# AT32UC3A1256 device description
Architecture: AVR32_UC3; Family: AVR UC3
Registers are 32-bit, read-write, reset 0x0 unless marked. A register's access mark holds for its fields unless they carry their own. Offsets are from the block's base; [hi:lo] are bit positions; {n}, {i} and the like mark numbered series; 'fields as' and 'values as' point back to an identical list.

## ABDAC — Audio Bitstream DAC
Instances: ABDAC 0xffff4000
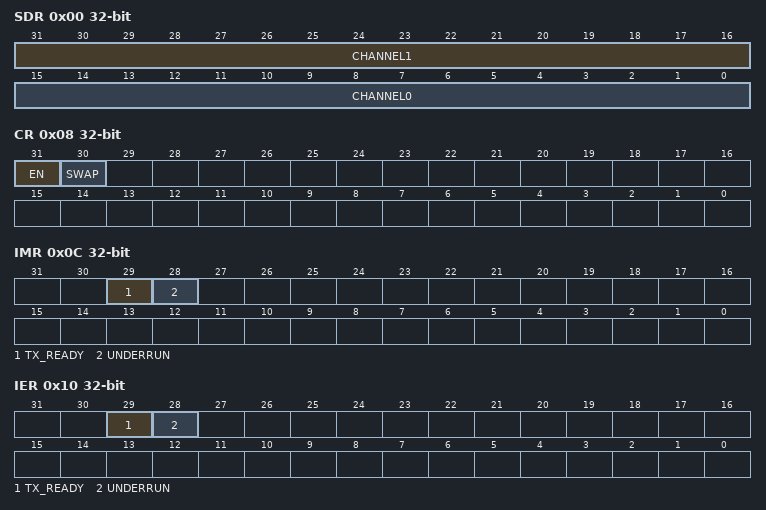
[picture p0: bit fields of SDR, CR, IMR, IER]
0x00 SDR — Sample Data Register
  [31:16] CHANNEL1 — Sample Data for Channel 1
  [15:0] CHANNEL0 — Sample Data for Channel 0
0x08 CR reset not defined — Control Register
  [31] EN — Enable Audio DAC.
  [30] SWAP — Swap Channels
0x0C IMR ro reset not defined — Interrupt Mask Register
  [29] TX_READY — TX Ready Interrupt Mask
  [28] UNDERRUN — Underrun Interrupt Mask
0x10 IER wo reset not defined — Interrupt Enable Register
  [29] TX_READY — TX Ready Interrupt Enable
  [28] UNDERRUN — Underrun Interrupt Enable
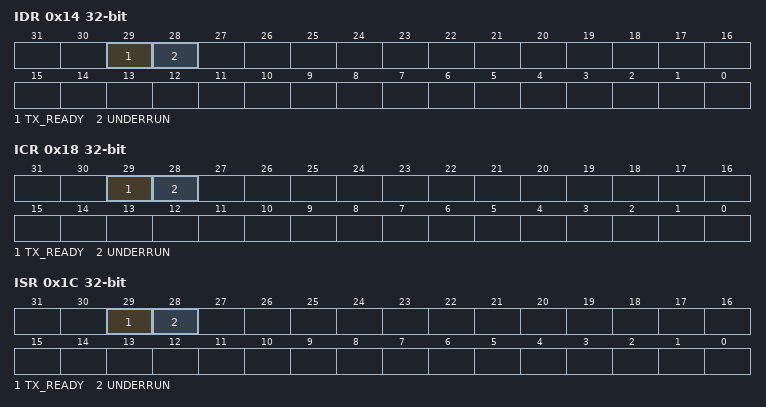
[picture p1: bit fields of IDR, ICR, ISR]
0x14 IDR wo reset not defined — Interupt Disable Register
  [29] TX_READY — TX Ready Interrupt Disable
  [28] UNDERRUN — Underrun Interrupt Disable
0x18 ICR wo reset not defined — Interrupt Clear Register
  [29] TX_READY — TX Ready Interrupt Clear
  [28] UNDERRUN — Underrun Interrupt Clear
0x1C ISR ro reset not defined — Interrupt Status Register
  [29] TX_READY — Interrupt Status Register
  [28] UNDERRUN — Interrupt Status Register

## EIC — External Interrupt Controller
Instances: EIC 0xffff0d80
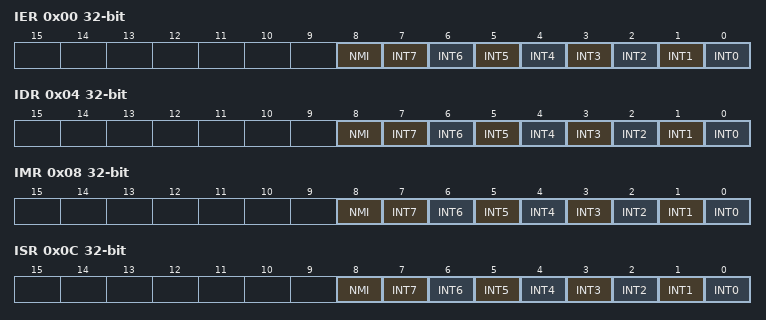
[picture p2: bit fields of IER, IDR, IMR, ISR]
0x00 IER wo — Interrupt Enable Register
  [8] NMI — External Non Maskable CPU interrupt
  [n] INT{n} (n=0..7) — External Interrupt {n}
0x04 IDR wo — Interrupt Disable Register
  fields as IER
0x08 IMR ro — Interrupt Mask Register
  fields as IER
0x0C ISR ro — Interrupt Status Register
  fields as IER
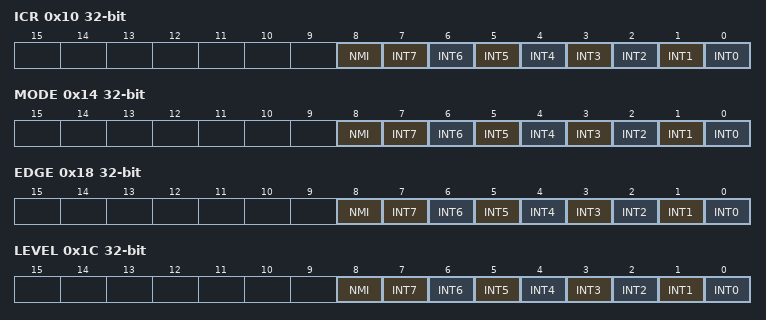
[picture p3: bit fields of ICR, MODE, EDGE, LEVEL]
0x10 ICR wo — Interrupt Clear Register
  fields as IER
0x14 MODE
  fields as IER
0x18 EDGE
  fields as IER
0x1C LEVEL
  fields as IER
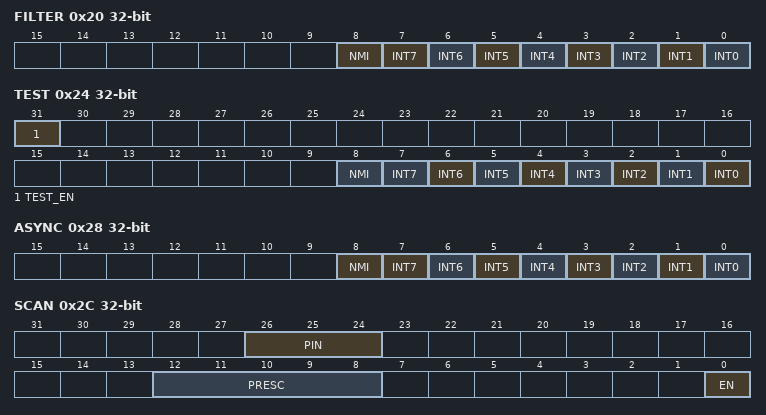
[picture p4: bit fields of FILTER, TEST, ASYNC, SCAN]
0x20 FILTER
  fields as IER
0x24 TEST
  [31] TEST_EN — Test Enable
  [8] NMI — External Non Maskable CPU interrupt
  [n] INT{n} (n=0..7) — External Interrupt {n}
0x28 ASYNC — Asynchronous Mode Register
  fields as IER
0x2C SCAN
  [26:24] PIN — SCAN Pin
  [12:8] PRESC — SCAN Prescale
  [0] EN — SCAN Enable
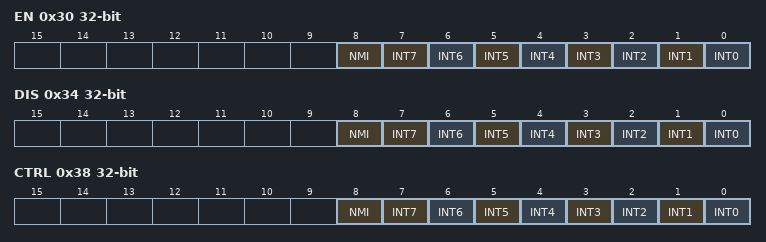
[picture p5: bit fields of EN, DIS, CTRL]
0x30 EN wo — Enable Register
  fields as IER
0x34 DIS wo — Disable Register
  fields as IER
0x38 CTRL — Control Register
  fields as IER

## FLASHC — Flash Controller
Instances: FLASHC 0xfffe1400
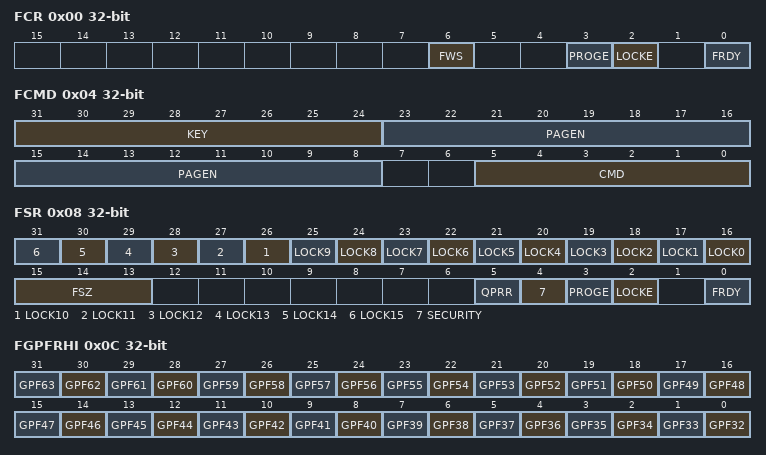
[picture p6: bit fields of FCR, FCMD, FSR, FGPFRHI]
0x00 FCR — Flash Controller Control Register
  [6] FWS, [3] PROGE, [2] LOCKE, [0] FRDY
0x04 FCMD — Flash Controller Command Register
  [31:24] KEY
    165=KEY
  [23:8] PAGEN
  [5:0] CMD — Command
    0=NOP; 1=WP; 2=EP; 3=CPB; 4=LP; 5=UP; 6=EA; 7=WGPB; 8=EGPB; 9=SSB; 10=PGPFB; 11=EAGPF; 12=QPR; 13=WUP; 14=EUP; 15=QPRUP
0x08 FSR reset not defined — Flash Controller Status Register
  [n+16] LOCK{n} (n=0..15)
  [15:13] FSZ
    0=32; 1=64; 2=128; 3=256; 4=384; 5=512; 6=768; 7=1024
  [5] QPRR
  [4] SECURITY
  [3] PROGE
  [2] LOCKE
  [0] FRDY
0x0C FGPFRHI ro reset not defined — Flash Controller General Purpose Fuse Register High
  [n-32] GPF{n} (n=32..63)
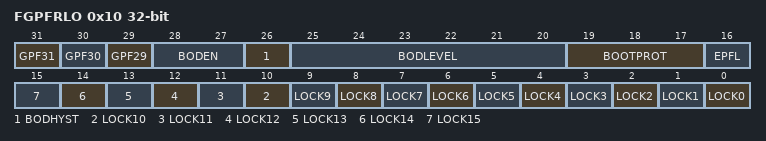
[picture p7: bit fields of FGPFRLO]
0x10 FGPFRLO ro reset not defined — Flash Controller General Purpose Fuse Register Low
  [31] GPF31, [30] GPF30, [29] GPF29, [28:27] BODEN, [26] BODHYST, [25:20] BODLEVEL, [19:17] BOOTPROT, [16] EPFL, [n] LOCK{n} (n=0..15)

## FREQM — Frequency Meter
Instances: FREQM 0xffff0d50
0x00 CTRL wo — Frequency Meter Control register
  [0] START — Start frequency measurement
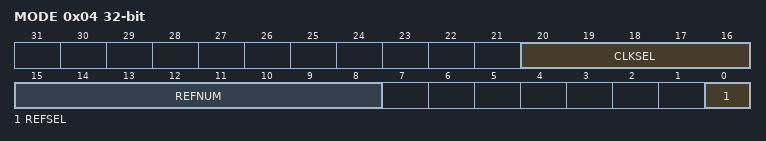
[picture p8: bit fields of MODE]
0x04 MODE — Frequency Meter Mode register
  [20:16] CLKSEL — Select the measured clock
    0=CPU; 1=HSB; 2=PBA; 3=PBB; 4=OSC0; 5=OSC1; 6=OSC32; 7=RCOSC; 8=PLL0; 9=PLL1; 10=CRIPLEL; {v}=GENCLK{v-11} (v=11..16)
  [15:8] REFNUM — Select the number of period of reference clock that will be used to measure frequency
  [0] REFSEL — Select reference clock
    0=REF_RCOSC; 1=REF_OSC32
0x08 STATUS ro — Frequency Meter Status register
  [0] BUSY — Frequency measurement on-going
0x0C VALUE — Frequency Meter Value register
  [23:0] VALUE — Measured frequency
0x10 IER wo — Frequency Meter Interrupt Enable Register
  [0] DONE — Frequency measurment done
0x14 IDR wo — Frequency Meter Interrupt Diable Register
  [0] DONE — Frequency measurment done
0x18 IMR ro — Frequency Meter Interrupt Mask Register
  [0] DONE — Frequency measurment done
0x1C ISR ro — Frequency Meter Interrupt Status Register
  [0] DONE — Frequency measurment done
0x20 ICR wo — Frequency Meter Interrupt Clear Register
  [0] DONE — Frequency measurment done
